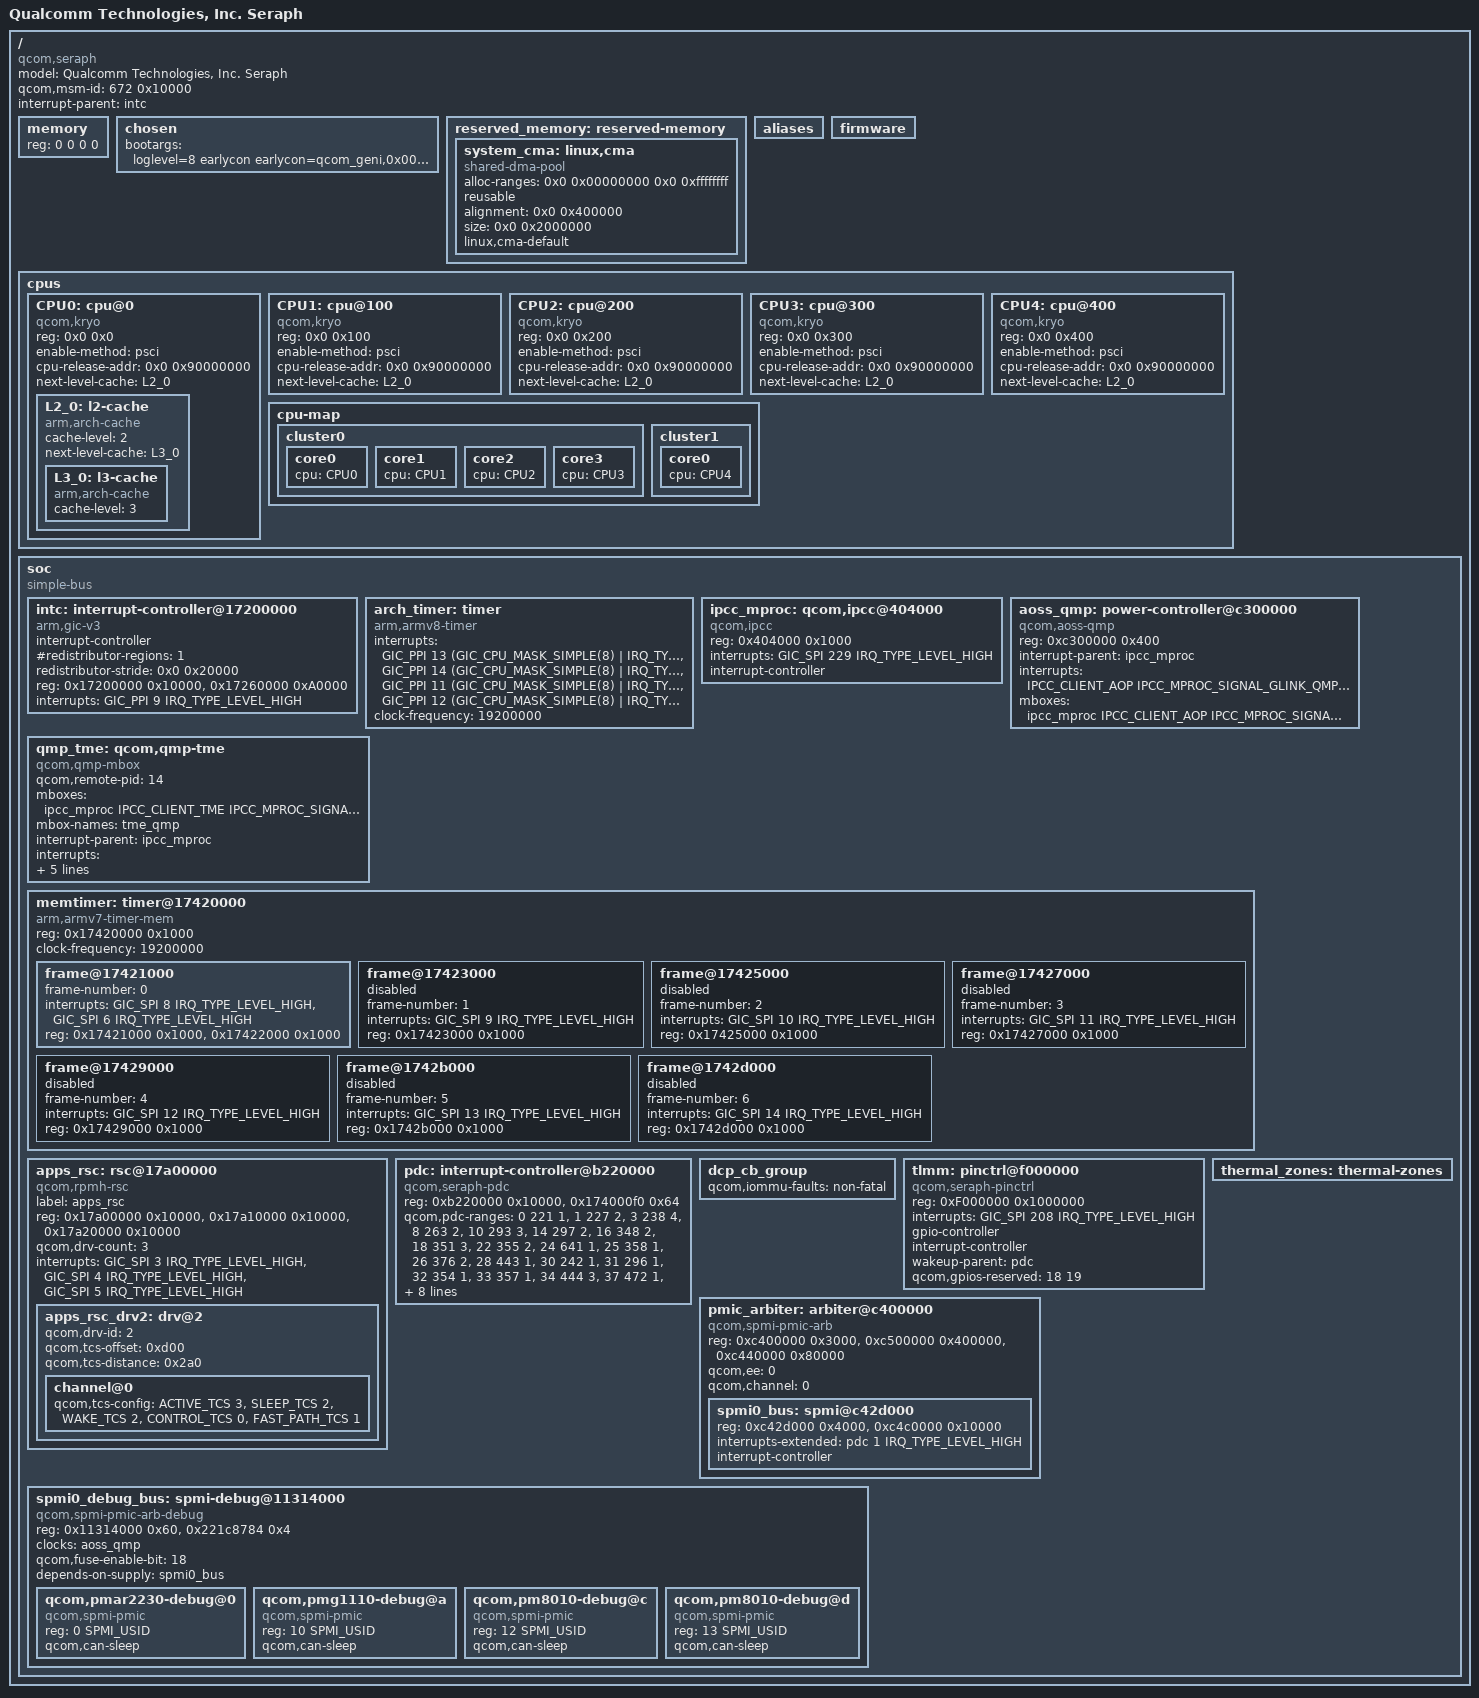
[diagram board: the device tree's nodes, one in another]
// SPDX-License-Identifier: BSD-3-Clause
/*
 * Copyright (c) Qualcomm Technologies, Inc. and/or its subsidiaries.
 */

#include <dt-bindings/interrupt-controller/arm-gic.h>
#include <dt-bindings/soc/qcom,rpmh-rsc.h>
#include <dt-bindings/soc/qcom,ipcc.h>
#include <dt-bindings/spmi/spmi.h>

/ {
	model = "Qualcomm Technologies, Inc. Seraph";
	compatible = "qcom,seraph";
	qcom,msm-id = <672 0x10000>;
	interrupt-parent = <&intc>;

	#address-cells = <2>;
	#size-cells = <2>;
	memory { device_type = "memory"; reg = <0 0 0 0>; };

	chosen: chosen {
		bootargs = "loglevel=8 earlycon earlycon=qcom_geni,0x00A94000 qcom_geni_serial.con_enabled=1 log_buf_len=256K  console=ttyMSM0,115200,n8 bootconfig";
	};

	reserved_memory: reserved-memory {};

	aliases { };

	firmware: firmware {};

	cpus {
		#address-cells = <2>;
		#size-cells = <0>;

		CPU0: cpu@0 {
			device_type = "cpu";
			compatible = "qcom,kryo";
			reg = <0x0 0x0>;
			enable-method = "psci";
			cpu-release-addr = <0x0 0x90000000>;
			next-level-cache = <&L2_0>;
			L2_0: l2-cache {
				compatible = "arm,arch-cache";
				cache-level = <2>;
				next-level-cache = <&L3_0>;

				L3_0: l3-cache {
					compatible = "arm,arch-cache";
					cache-level = <3>;
				};
			};
		};

		CPU1: cpu@100 {
			device_type = "cpu";
			compatible = "qcom,kryo";
			reg = <0x0 0x100>;
			enable-method = "psci";
			cpu-release-addr = <0x0 0x90000000>;
			next-level-cache = <&L2_0>;
		};

		CPU2: cpu@200 {
			device_type = "cpu";
			compatible = "qcom,kryo";
			reg = <0x0 0x200>;
			enable-method = "psci";
			cpu-release-addr = <0x0 0x90000000>;
			next-level-cache = <&L2_0>;
		};

		CPU3: cpu@300 {
			device_type = "cpu";
			compatible = "qcom,kryo";
			reg = <0x0 0x300>;
			enable-method = "psci";
			cpu-release-addr = <0x0 0x90000000>;
			next-level-cache = <&L2_0>;
		};

		CPU4: cpu@400 {
			device_type = "cpu";
			compatible = "qcom,kryo";
			reg = <0x0 0x400>;
			enable-method = "psci";
			cpu-release-addr = <0x0 0x90000000>;
			next-level-cache = <&L2_0>;
		};

		cpu-map {
			cluster0 {
				core0 {
					cpu = <&CPU0>;
				};

				core1 {
					cpu = <&CPU1>;
				};

				core2 {
					cpu = <&CPU2>;
				};

				core3 {
					cpu = <&CPU3>;
				};
			};

			cluster1 {
				core0 {
					cpu = <&CPU4>;
				};
			};
		};
	};

	soc: soc { };

};

&soc {
	#address-cells = <1>;
	#size-cells = <1>;

	ranges = <0 0 0 0xffffffff>;
	compatible = "simple-bus";

	intc: interrupt-controller@17200000 {
		compatible = "arm,gic-v3";
		#interrupt-cells = <3>;
		interrupt-controller;
		#redistributor-regions = <1>;
		redistributor-stride = <0x0 0x20000>;
		reg = <0x17200000 0x10000>,       /* GICD */
		     <0x17260000 0xA0000>;       /* GICR * 5 */
		interrupts = <GIC_PPI 9 IRQ_TYPE_LEVEL_HIGH>;
	};

	arch_timer: timer {
		compatible = "arm,armv8-timer";
		interrupts = <GIC_PPI 13 (GIC_CPU_MASK_SIMPLE(8) | IRQ_TYPE_LEVEL_LOW)>,
			     <GIC_PPI 14 (GIC_CPU_MASK_SIMPLE(8) | IRQ_TYPE_LEVEL_LOW)>,
			     <GIC_PPI 11 (GIC_CPU_MASK_SIMPLE(8) | IRQ_TYPE_LEVEL_LOW)>,
			     <GIC_PPI 12 (GIC_CPU_MASK_SIMPLE(8) | IRQ_TYPE_LEVEL_LOW)>;
		clock-frequency = <19200000>;
	};

	ipcc_mproc: qcom,ipcc@404000 {
		compatible = "qcom,ipcc";
		reg = <0x404000 0x1000>;
		interrupts = <GIC_SPI 229 IRQ_TYPE_LEVEL_HIGH>;
		interrupt-controller;
		#interrupt-cells = <3>;
		#mbox-cells = <2>;
	};

	aoss_qmp: power-controller@c300000 {
		compatible = "qcom,aoss-qmp";
		reg = <0xc300000 0x400>;
		interrupt-parent = <&ipcc_mproc>;
		interrupts = <IPCC_CLIENT_AOP
			      IPCC_MPROC_SIGNAL_GLINK_QMP
			      IRQ_TYPE_EDGE_RISING>;
		mboxes = <&ipcc_mproc IPCC_CLIENT_AOP
			  IPCC_MPROC_SIGNAL_GLINK_QMP>;

		#power-domain-cells = <1>;
		#clock-cells = <0>;
	};

	qmp_tme: qcom,qmp-tme {
		compatible = "qcom,qmp-mbox";
		qcom,remote-pid = <14>;
		mboxes = <&ipcc_mproc IPCC_CLIENT_TME
			  IPCC_MPROC_SIGNAL_GLINK_QMP>;
		mbox-names = "tme_qmp";
		interrupt-parent = <&ipcc_mproc>;
		interrupts = <IPCC_CLIENT_TME
			      IPCC_MPROC_SIGNAL_GLINK_QMP
			      IRQ_TYPE_EDGE_RISING>;

		label = "tme";
		qcom,early-boot;
		priority = <0>;
		mbox-desc-offset = <0x0>;
		#mbox-cells = <1>;
	};

	memtimer: timer@17420000 {
		#address-cells = <1>;
		#size-cells = <1>;
		ranges;
		compatible = "arm,armv7-timer-mem";
		reg = <0x17420000 0x1000>;
		clock-frequency = <19200000>;

		frame@17421000 {
			frame-number = <0>;
			interrupts = <GIC_SPI 8 IRQ_TYPE_LEVEL_HIGH>,
				     <GIC_SPI 6 IRQ_TYPE_LEVEL_HIGH>;
			reg = <0x17421000 0x1000>,
			      <0x17422000 0x1000>;
		};

		frame@17423000 {
			frame-number = <1>;
			interrupts = <GIC_SPI 9 IRQ_TYPE_LEVEL_HIGH>;
			reg = <0x17423000 0x1000>;
			status = "disabled";
		};

		frame@17425000 {
			frame-number = <2>;
			interrupts = <GIC_SPI 10 IRQ_TYPE_LEVEL_HIGH>;
			reg = <0x17425000 0x1000>;
			status = "disabled";
		};

		frame@17427000 {
			frame-number = <3>;
			interrupts = <GIC_SPI 11 IRQ_TYPE_LEVEL_HIGH>;
			reg = <0x17427000 0x1000>;
			status = "disabled";
		};

		frame@17429000 {
			frame-number = <4>;
			interrupts = <GIC_SPI 12 IRQ_TYPE_LEVEL_HIGH>;
			reg = <0x17429000 0x1000>;
			status = "disabled";
		};

		frame@1742b000 {
			frame-number = <5>;
			interrupts = <GIC_SPI 13 IRQ_TYPE_LEVEL_HIGH>;
			reg = <0x1742b000 0x1000>;
			status = "disabled";
		};

		frame@1742d000 {
			frame-number = <6>;
			interrupts = <GIC_SPI 14 IRQ_TYPE_LEVEL_HIGH>;
			reg = <0x1742d000 0x1000>;
			status = "disabled";
		};
	};

	apps_rsc: rsc@17a00000 {
		label = "apps_rsc";
		compatible = "qcom,rpmh-rsc";
		reg = <0x17a00000 0x10000>,
		      <0x17a10000 0x10000>,
		      <0x17a20000 0x10000>;
		reg-names = "drv-0", "drv-1", "drv-2";
		qcom,drv-count = <3>;
		interrupts = <GIC_SPI 3 IRQ_TYPE_LEVEL_HIGH>,
			     <GIC_SPI 4 IRQ_TYPE_LEVEL_HIGH>,
			     <GIC_SPI 5 IRQ_TYPE_LEVEL_HIGH>;

		apps_rsc_drv2: drv@2 {
			qcom,drv-id = <2>;
			qcom,tcs-offset = <0xd00>;
			qcom,tcs-distance = <0x2a0>;
			channel@0 {
				qcom,tcs-config = <ACTIVE_TCS    3>,
						  <SLEEP_TCS     2>,
						  <WAKE_TCS      2>,
						  <CONTROL_TCS   0>,
						  <FAST_PATH_TCS 1>;
			};
		};
	};

	pdc: interrupt-controller@b220000 {
		compatible = "qcom,seraph-pdc", "qcom,pdc";
		reg = <0xb220000 0x10000>, <0x174000f0 0x64>;
		qcom,pdc-ranges = <0 221 1>, <1 227 2>, <3 238 4>,
				  <8 263 2>, <10 293 3>, <14 297 2>,
				  <16 348 2>, <18 351 3>, <22 355 2>,
				  <24 641 1>, <25 358 1>, <26 376 2>,
				  <28 443 1>, <30 242 1>, <31 296 1>,
				  <32 354 1>, <33 357 1>, <34 444 3>,
				  <37 472 1>, <40 447 1>, <41 461 1>,
				  <42 473 1>, <43 462 1>, <44 584 1>,
				  <45 586 1>, <47 607 2>, <49 642 1>,
				  <50 656 1>, <51 527 1>, <61 505 1>,
				  <62 605 1>, <63 372 2>, <65 378 1>,
				  <66 431 1>, <70 528 46>, <116 609 31>,
				  <147 63 1>, <148 716 12>, <160 251 5>,
				  <165 379 1>;
		#interrupt-cells = <2>;
		interrupt-parent = <&intc>;
		interrupt-controller;
	};

	dcp_cb_group: dcp_cb_group {
		qcom,iommu-faults = "non-fatal";
	};

	tlmm: pinctrl@f000000 {
		compatible = "qcom,seraph-pinctrl";
		reg = <0xF000000 0x1000000>;
		interrupts = <GIC_SPI 208 IRQ_TYPE_LEVEL_HIGH>;
		gpio-controller;
		#gpio-cells = <2>;
		interrupt-controller;
		#interrupt-cells = <2>;
		wakeup-parent = <&pdc>;
		qcom,gpios-reserved = <18 19>;
	};

	thermal_zones: thermal-zones {};

	pmic_arbiter: arbiter@c400000 {
		compatible = "qcom,spmi-pmic-arb";
		reg = <0xc400000 0x3000>,
		      <0xc500000 0x400000>,
		      <0xc440000 0x80000>;
		reg-names = "core", "chnls", "obsrvr";

		qcom,ee = <0>;
		qcom,channel = <0>;

		#address-cells = <1>;
		#size-cells = <1>;
		ranges;

		spmi0_bus: spmi@c42d000 {
			reg = <0xc42d000 0x4000>,
			      <0xc4c0000 0x10000>;
			reg-names = "cnfg", "intr";

			interrupt-names = "periph_irq";
			interrupts-extended = <&pdc 1 IRQ_TYPE_LEVEL_HIGH>;
			interrupt-controller;
			#interrupt-cells = <4>;

			#address-cells = <2>;
			#size-cells = <0>;
		};
	};

	spmi0_debug_bus: spmi-debug@11314000 {
		compatible = "qcom,spmi-pmic-arb-debug";
		reg = <0x11314000 0x60>, <0x221c8784 0x4>;
		reg-names = "core", "fuse";
		clocks = <&aoss_qmp>;
		clock-names = "core_clk";
		qcom,fuse-enable-bit = <18>;
		#address-cells = <2>;
		#size-cells = <0>;
		depends-on-supply = <&spmi0_bus>;

		qcom,pmar2230-debug@0 {
			compatible = "qcom,spmi-pmic";
			reg = <0 SPMI_USID>;
			#address-cells = <2>;
			#size-cells = <0>;
			qcom,can-sleep;
		};

		qcom,pmg1110-debug@a {
			compatible = "qcom,spmi-pmic";
			reg = <10 SPMI_USID>;
			#address-cells = <2>;
			#size-cells = <0>;
			qcom,can-sleep;
		};

		qcom,pm8010-debug@c {
			compatible = "qcom,spmi-pmic";
			reg = <12 SPMI_USID>;
			#address-cells = <2>;
			#size-cells = <0>;
			qcom,can-sleep;
		};

		qcom,pm8010-debug@d {
			compatible = "qcom,spmi-pmic";
			reg = <13 SPMI_USID>;
			#address-cells = <2>;
			#size-cells = <0>;
			qcom,can-sleep;
		};
	};

};

&reserved_memory {
	#address-cells = <2>;
	#size-cells = <2>;
	ranges;

	/* global autoconfigured region for contiguous allocations */
	system_cma: linux,cma {
		compatible = "shared-dma-pool";
		alloc-ranges = <0x0 0x00000000 0x0 0xffffffff>;
		reusable;
		alignment = <0x0 0x400000>;
		size = <0x0 0x2000000>;
		linux,cma-default;
	};
};

#include "seraph-reserved-memory.dtsi"
#include "msm-arm-smmu-seraph.dtsi"
